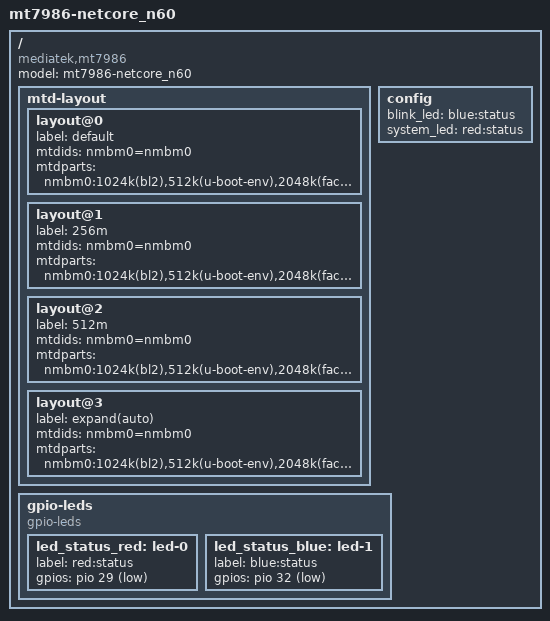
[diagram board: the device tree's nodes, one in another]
// SPDX-License-Identifier: GPL-2.0

/dts-v1/;
#include "mt7986a-netcore-n60.dtsi"

/ {
	model = "mt7986-netcore_n60";
	compatible = "mediatek,mt7986", "mediatek,mt7986-rfb";

	mtd-layout {
		layout@0 {
			label = "default";
			mtdids = "nmbm0=nmbm0";
			mtdparts = "nmbm0:1024k(bl2),512k(u-boot-env),2048k(factory),2048k(fip),117248k(ubi)";
		};

		layout@1 {
			label = "256m";
			mtdids = "nmbm0=nmbm0";
			mtdparts = "nmbm0:1024k(bl2),512k(u-boot-env),2048k(factory),2048k(fip),-(ubi)";
		};

		layout@2 {
			label = "512m";
			mtdids = "nmbm0=nmbm0";
			mtdparts = "nmbm0:1024k(bl2),512k(u-boot-env),2048k(factory),2048k(fip),-(ubi)";
		};

		layout@3 {
			label = "expand(auto)";
			mtdids = "nmbm0=nmbm0";
			mtdparts = "nmbm0:1024k(bl2),512k(u-boot-env),2048k(factory),2048k(fip),-(ubi)";
		};
	};

	config {
		blink_led = "blue:status";
		system_led = "red:status";
	};

	gpio-leds {
		compatible = "gpio-leds";

		led_status_red: led-0 {
			label = "red:status";
			gpios = <&pio 29 GPIO_ACTIVE_LOW>;
		};

		led_status_blue: led-1 {
			label = "blue:status";
			gpios = <&pio 32 GPIO_ACTIVE_LOW>;
		};
	};
};
